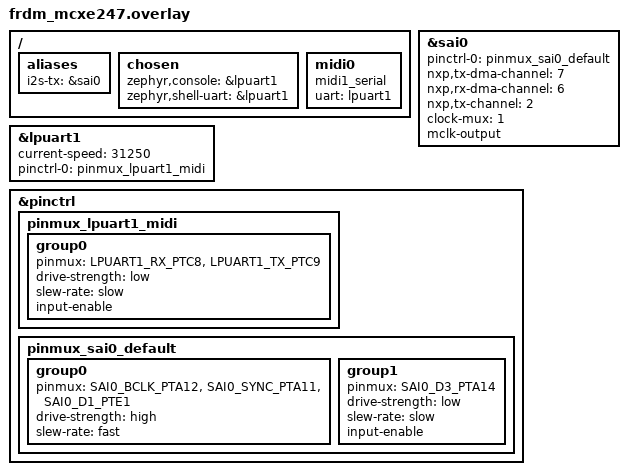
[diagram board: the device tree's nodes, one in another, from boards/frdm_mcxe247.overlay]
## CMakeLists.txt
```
# Copyright 2026 Jan-Willem Smaal <usenet@gispen.org>
# SPDX-License-Identifier: Apache-2.0

cmake_minimum_required(VERSION 3.20.0)
set(KCONFIG_ROOT ${CMAKE_CURRENT_SOURCE_DIR}/Kconfig)
find_package(Zephyr REQUIRED HINTS $ENV{ZEPHYR_BASE})
project(midi-synth)

set(GEN_LUTS_SCRIPT ${CMAKE_CURRENT_SOURCE_DIR}/scripts/gen_luts.py)
set(LUTS_HEADER ${CMAKE_CURRENT_BINARY_DIR}/include/synth_luts_generated.h)

add_custom_command(
    OUTPUT ${LUTS_HEADER}
    COMMAND ${CMAKE_COMMAND} -E make_directory ${CMAKE_CURRENT_BINARY_DIR}/include
    COMMAND python3 ${GEN_LUTS_SCRIPT} ${CONFIG_AUDIO_SAMPLE_RATE} ${LUTS_HEADER}
    DEPENDS ${GEN_LUTS_SCRIPT}
)

target_sources(app PRIVATE 
    src/main.c 
    src/audio.c 
    src/synth_engine.c
    src/midi_handler.c
    src/adsr.c
    src/waveform_selector.c
)

target_include_directories(app PRIVATE src ${CMAKE_CURRENT_BINARY_DIR}/include)
set_source_files_properties(src/synth_engine.c PROPERTIES OBJECT_DEPENDS ${LUTS_HEADER})
```

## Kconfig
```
# Copyright 2026 Jan-Willem Smaal <usenet@gispen.org>
# SPDX-License-Identifier: Apache-2.0

menu "MIDI Synth Options"

config AUDIO_SAMPLE_RATE
	int "Sample Rate (Hz)"
	default 96000
	help
	  System audio sample rate. Possible values 8000, 16000, 32000 etc.

config VOICECARD_VOICES
	int "Number of voices"
	default 16
	help
	  Number of voices support.  Multiples of 2.  2, 4, 8, 16 etc...

config AUDIO_BIT_WIDTH
	int "Sample Bit Width"
	default 16
	help
	  Audio bit depth (currently only 16 bit works!)

endmenu

source "Kconfig.zephyr"
```

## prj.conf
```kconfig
# Copyright 2026 Jan-Willem Smaal <usenet@gispen.org>
# SPDX-License-Identifier: Apache-2.0

# General
CONFIG_MAIN_STACK_SIZE=2048
CONFIG_BOOT_BANNER=y

# I2S and Audio
CONFIG_I2S=y
CONFIG_AUDIO_SAMPLE_RATE=96000
CONFIG_AUDIO_BIT_WIDTH=16

# CMSIS-DSP
CONFIG_DSP=y
CONFIG_CMSIS_DSP=y
CONFIG_CMSIS_DSP_FASTMATH=y

# MIDI 1.0 Library
CONFIG_MIDI1_SERIAL=y
CONFIG_MIDI1_SERIAL_ISR_MSGQ_SIZE_MS=128
CONFIG_MIDI1_HARMONIC=y
CONFIG_SERIAL=y
CONFIG_UART_INTERRUPT_DRIVEN=y

# GPIO
CONFIG_GPIO=y

# Logging
CONFIG_LOG=y
#CONFIG_LOG_DEFAULT_LEVEL=3
CONFIG_I2S_LOG_LEVEL_ERR=y

# Floating Point Support for Shell/Logging
CONFIG_CBPRINTF_FP_SUPPORT=y

# Synthesizer Configuration
CONFIG_VOICECARD_VOICES=32
```

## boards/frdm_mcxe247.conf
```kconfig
# Copyright 2026 Jan-Willem Smaal <usenet@gispen.org>
# SPDX-License-Identifier: Apache-2.0
CONFIG_I2S_HAS_PLL_SETTING=n
```

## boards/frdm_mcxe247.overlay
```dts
/*
 * Copyright 2026 Jan-Willem Smaal <usenet@gispen.org>
 * SPDX-License-Identifier: Apache-2.0
 */

#include <nxp/mcx/MCXE247VLQ-pinctrl.h>

/ {
	aliases {
		i2s-tx = &sai0;
	};

	chosen {
		/* MIDI/Console on mikroBUS UART (PTC8/PTC9) */
		zephyr,console = &lpuart1;
		zephyr,shell-uart = &lpuart1;
	};

	midi0: midi0 {
		status = "okay";
		compatible = "midi1_serial";
		uart = <&lpuart1>;
	};
};

&sai0 {
	status = "okay";
	pinctrl-0 = <&pinmux_sai0_default>;
	pinctrl-names = "default";
	
	/* REQUIRED properties from binding documentation */
	nxp,tx-dma-channel = <7>;
	nxp,rx-dma-channel = <6>;
	
	/* User Truth: J1 Pin 5 is PTE1 which is SAI0_D1 (Channel 1) */
	nxp,tx-channel = <2>; 
	
	/* Select standard functional clock for SAI root */
	clock-mux = <1>; 
	
	mclk-output;
};

/* MIDI/Console on mikroBUS UART (PTC8/PTC9) */
&lpuart1 {
	status = "okay";
	current-speed = <31250>;
	pinctrl-0 = <&pinmux_lpuart1_midi>;
	pinctrl-names = "default";
};

&pinctrl {
	/* Standard pins with input-enable for RX */
	pinmux_lpuart1_midi: pinmux_lpuart1_midi {
		group0 {
			pinmux = <LPUART1_RX_PTC8>,
				 <LPUART1_TX_PTC9>;
			drive-strength = "low";
			slew-rate = "slow";
			input-enable;
		};
	};

	/* SAI0 (Verified User Truth Mapping) */
	pinmux_sai0_default: pinmux_sai0_default {
		group0 {
			pinmux = <SAI0_BCLK_PTA12>,   /* J1 Pin 9  - Bit Clock */
				 <SAI0_SYNC_PTA11>,   /* J1 Pin 7  - Frame Sync (LRCK) */
				 <SAI0_D1_PTE1>;      /* J1 Pin 5  - Data Out (TX_DAT) */
			drive-strength = "high";
			slew-rate = "fast";
		};
		group1 {
			pinmux = <SAI0_D3_PTA14>;     /* J1 Pin 15 - Data In (RX_DAT) */
			drive-strength = "low";
			slew-rate = "slow";
			input-enable;
		};
	};
};
```

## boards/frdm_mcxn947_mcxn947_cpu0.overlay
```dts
/*
 * Copyright 2026 Jan-Willem Smaal <usenet@gispen.org>
 * SPDX-License-Identifier: Apache-2.0
 */

/ {
	aliases {
		i2s-tx = &sai1;
		sw2    = &user_button_2;
	};

	midi0: midi0 {
		status = "okay";
		compatible = "midi1_serial";
		uart = <&flexcomm2_lpuart2>;
	};
};

/* Enable SW2 (defined but disabled in the upstream board DTSI) */
&user_button_2 {
	status = "okay";
};

&sai1 {
	status = "okay";
	pinctrl-0 = <&pinmux_sai1_custom>;
	pinctrl-names = "default";
	nxp,tx-channel = <1>; /* Bitmask: 1 = Channel 0 (TXD0) */
	mclk-output;          /* MANDATORY for MCXN947 */
};

/* MIDI on Arduino D0/D1 */
&flexcomm2_lpuart2 {
	status = "okay";
	current-speed = <31250>;
};

&pinctrl {
	pinmux_sai1_custom: pinmux_sai1_custom {
		group0 {
			pinmux = <SAI1_TX_BCLK_PIO3_16>,   /* J1 Pin 1  - Bit Clock */
				 <SAI1_TX_FS_PIO3_17>,     /* J1 Pin 11 - Frame Sync (LRCK) */
				 <SAI1_TXD0_PIO3_20>,      /* J1 Pin 5  - Data Out */
				 <SAI1_RX_BCLK_PIO3_18>;   /* J1 Pin 9  - Bit Clock (Shared) */
			drive-strength = "high";
			slew-rate = "fast";
			input-enable;
		};
	};
};
```

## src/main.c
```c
/*
 * Copyright 2026 Jan-Willem Smaal <usenet@gispen.org>
 * SPDX-License-Identifier: Apache-2.0
 */

/**
 * @file main.c
 * @brief MIDI Sine Wave Synthesizer Main Entry Point
 * @author Jan-Willem Smaal <usenet@gispen.org>
 */

#include <zephyr/kernel.h>
#include <zephyr/logging/log.h>
#include <zephyr/drivers/i2s.h>
#include "audio.h"
#include "synth_engine.h"
#include "midi_handler.h"
#include "waveform_selector.h"

LOG_MODULE_REGISTER(midi_synth, CONFIG_LOG_DEFAULT_LEVEL);

K_MEM_SLAB_DEFINE_STATIC(rx_slab, 512, 16, 32); /**< Dummy for clock generator */

static const struct device *const i2s_dev = DEVICE_DT_GET(DT_ALIAS(i2s_tx));

static int configure_rx(void)
{
	struct i2s_config conf;

	conf.word_size = CONFIG_AUDIO_BIT_WIDTH;
	conf.channels = 2;
	conf.format = I2S_FMT_DATA_FORMAT_I2S;
	conf.options = I2S_OPT_BIT_CLK_CONTROLLER | I2S_OPT_FRAME_CLK_CONTROLLER;
	conf.frame_clk_freq = CONFIG_AUDIO_SAMPLE_RATE;
	conf.block_size = 128 * 2 * (CONFIG_AUDIO_BIT_WIDTH / 8);
	conf.timeout = 50;
	conf.mem_slab = &rx_slab;

	return i2s_configure(i2s_dev, I2S_DIR_RX, &conf);
}

/**
 * @brief RX Sink Thread
 * Drains the dummy RX queue to keep clock generation running without ENOMEM.
 */
static void rx_sink_thread_fn(void *p1, void *p2, void *p3)
{
	void *rx_buffer;
	size_t size;
	int ret;

	ARG_UNUSED(p1);
	ARG_UNUSED(p2);
	ARG_UNUSED(p3);

	while (1) {
		ret = i2s_read(i2s_dev, &rx_buffer, &size);
		if (ret == 0) {
			k_mem_slab_free(&rx_slab, rx_buffer);
		} else {
			/* For any error (including -EAGAIN from a timeout or -EIO from overrun), drop and restart the stream */
			LOG_WRN("I2S RX error %d — resetting RX stream", ret);
			i2s_trigger(i2s_dev, I2S_DIR_RX, I2S_TRIGGER_DROP);
			ret = configure_rx();
			if (ret < 0) {
				LOG_ERR("I2S RX reconfigure failed: %d", ret);
			}

			/* Attempt to restart RX stream */
			ret = i2s_trigger(i2s_dev, I2S_DIR_RX, I2S_TRIGGER_START);
			if (ret < 0) {
				LOG_ERR("Failed to restart I2S RX: %d", ret);
				k_sleep(K_MSEC(10));
			}
		}
	}
}

K_THREAD_DEFINE(rx_sink_tid, 1024, rx_sink_thread_fn, NULL, NULL, NULL, -3, 0, K_TICKS_FOREVER);

int main(void)
{
	int ret;

	/* Application Banner */
	LOG_INF("\n\n");
	LOG_INF("##############################################");
	LOG_INF("# MIDI Polyphonic Sine Synthesizer");
	LOG_INF("# By: Jan-Willem Smaal <usenet@gispen.org>");
	LOG_INF("# Hardware: %-26s", CONFIG_BOARD_TARGET);
	LOG_INF("# Build:    %-26s", __DATE__ " " __TIME__);
	LOG_INF("##############################################");
	LOG_INF("Initializing system components...");

	if (!device_is_ready(i2s_dev)) {
		LOG_ERR("I2S device not ready for RX clock generation");
		return -ENODEV;
	}

	ret = configure_rx();
	if (ret < 0) {
		LOG_ERR("I2S RX configure failed: %d", ret);
		return ret;
	}

	/* Initialize Synthesizer DSP */
	synth_engine_init();

	/* Initialize Audio System */
	ret = audio_system_init();
	if (ret < 0) {
		LOG_ERR("Audio system initialization failed: %d", ret);
		return ret;
	}

	/* Initialize MIDI System */
	ret = midi_system_init();
	if (ret < 0) {
		LOG_ERR("MIDI system initialization failed: %d", ret);
		return ret;
	}

	/* Initialize waveform selector (SW2) */
	ret = waveform_selector_init();
	if (ret < 0) {
		LOG_ERR("Waveform selector initialization failed: %d", ret);
		return ret;
	}

	/* Start Clocks (via RX) */
	ret = i2s_trigger(i2s_dev, I2S_DIR_RX, I2S_TRIGGER_START);
	if (ret < 0) {
		LOG_WRN("I2S RX (Clocks) start failed: %d", ret);
	}
	k_thread_start(rx_sink_tid);

	LOG_INF("System operational.");

	while (1) {
		k_sleep(K_FOREVER);
	}

	return 0;
}
```

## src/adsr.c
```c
/*
 * Copyright 2026 Jan-Willem Smaal <usenet@gispen.org>
 * SPDX-License-Identifier: Apache-2.0
 */

/**
 * @file adsr.c
 * @brief ADSR implementation
 * @author Jan-Willem Smaal <usenet@gispen.org>
 */
#include "adsr.h"

void adsr_trigger_on(struct adsr *padsr, struct adsr_param param)
{
	padsr->state = ATTACK;
	padsr->lifetime = param.attack;
	padsr->initial_lifetime = param.attack;
	padsr->start_gain = 0;
	padsr->gain_accum = 0;

	if (param.attack > 0) {
		padsr->gain_step = ((int32_t)32767 << 16) / (int32_t)param.attack;
	} else {
		padsr->gain_step = 0;
		padsr->gain_accum = (int32_t)32767 << 16;
	}
	padsr->current_gain = (q15_t)(padsr->gain_accum >> 16);
}

void adsr_trigger_off(struct adsr *padsr, struct adsr_param param)
{
	padsr->state = RELEASE;
	padsr->lifetime = param.release;
	padsr->initial_lifetime = param.release;
	padsr->start_gain = padsr->current_gain;
	padsr->gain_accum = (int32_t)padsr->start_gain << 16;

	if (param.release > 0) {
		padsr->gain_step = -((int32_t)padsr->start_gain << 16) / (int32_t)param.release;
	} else {
		padsr->gain_step = 0;
		padsr->gain_accum = 0;
	}
	padsr->current_gain = (q15_t)(padsr->gain_accum >> 16);
}

enum adsr_state adsr_process(struct adsr *padsr, struct adsr_param param, uint32_t delta_samples,
			     bool use_log)
{
	enum adsr_state ret_state = padsr->state;
	uint32_t active_delta = delta_samples;

	/* Don't do anything when we are in the END state */
	if (ret_state == END) {
		padsr->lifetime = 0;
		return ret_state;
	}

	bool keep_transitioning = true;

	/* State transition when lifetime expires */
	while (padsr->lifetime == 0 && padsr->state != END && keep_transitioning) {
		padsr->start_gain = padsr->current_gain;
		switch (padsr->state) {
		case ATTACK:
			padsr->state = DECAY;
			padsr->lifetime = param.decay;
			padsr->initial_lifetime = param.decay;
			padsr->gain_accum = (int32_t)padsr->start_gain << 16;
			if (param.decay > 0) {
				int32_t target_gain = padsr->sustain_level;

				padsr->gain_step = ((target_gain - padsr->start_gain) << 16) / (int32_t)param.decay;
			} else {
				padsr->gain_step = 0;
				padsr->gain_accum = (int32_t)padsr->sustain_level << 16;
			}
			padsr->current_gain = (q15_t)(padsr->gain_accum >> 16);
			break;
		case DECAY:
			padsr->state = SUSTAIN;
			padsr->lifetime = param.sustain;
			padsr->initial_lifetime = param.sustain;
			padsr->gain_accum = (int32_t)padsr->sustain_level << 16;
			padsr->gain_step = 0;
			padsr->current_gain = padsr->sustain_level;
			break;
		case SUSTAIN:
			if (param.sustain > 0) {
				padsr->state = RELEASE;
				padsr->lifetime = param.release;
				padsr->initial_lifetime = param.release;
				padsr->gain_accum = (int32_t)padsr->current_gain << 16;
				if (param.release > 0) {
					padsr->gain_step = -((int32_t)padsr->current_gain << 16) / (int32_t)param.release;
				} else {
					padsr->gain_step = 0;
					padsr->gain_accum = 0;
				}
				padsr->current_gain = (q15_t)(padsr->gain_accum >> 16);
			} else {
				keep_transitioning = false;
			}
			break;
		case RELEASE:
			padsr->state = END;
			padsr->lifetime = 0;
			padsr->initial_lifetime = 0;
			padsr->gain_accum = 0;
			padsr->gain_step = 0;
			padsr->current_gain = 0;
			break;
		default:
			keep_transitioning = false;
			break;
		}
	}

	if (padsr->state == END) {
		padsr->lifetime = 0;
		return ret_state;
	}

	/* Subtract the delta from the lifetime */
	if (active_delta >= padsr->lifetime) {
		active_delta = padsr->lifetime;
		padsr->lifetime = 0;
	} else {
		padsr->lifetime = padsr->lifetime - active_delta;
	}

	/* Perform incremental step accumulation */
	switch (padsr->state) {
	case ATTACK:
	case DECAY:
	case RELEASE:
		padsr->gain_accum += padsr->gain_step * active_delta;
		/* Boundary clamping */
		if (padsr->state == ATTACK) {
			if (padsr->gain_accum > ((int32_t)32767 << 16)) {
				padsr->gain_accum = (int32_t)32767 << 16;
			}
		} else if (padsr->state == DECAY) {
			if (padsr->gain_step < 0) {
				if (padsr->gain_accum < ((int32_t)padsr->sustain_level << 16)) {
					padsr->gain_accum = (int32_t)padsr->sustain_level << 16;
				}
			} else if (padsr->gain_step > 0) {
				if (padsr->gain_accum > ((int32_t)padsr->sustain_level << 16)) {
					padsr->gain_accum = (int32_t)padsr->sustain_level << 16;
				}
			}
		} else if (padsr->state == RELEASE) {
			if (padsr->gain_accum < 0) {
				padsr->gain_accum = 0;
			}
		}
		padsr->current_gain = (q15_t)(padsr->gain_accum >> 16);
		break;
	case SUSTAIN:
		padsr->current_gain = padsr->sustain_level;
		break;
	case END:
		padsr->current_gain = 0;
		break;
	}

	if (use_log) {
		padsr->current_gain =
			(q15_t)(((int32_t)padsr->current_gain * padsr->current_gain) >> 15);
	}

	return ret_state;
}

/* EOF */
```

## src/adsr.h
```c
/*
 * Copyright 2026 Jan-Willem Smaal <usenet@gispen.org>
 * SPDX-License-Identifier: Apache-2.0
 */

/**
 * @file adsr.h
 * @brief ADSR implementation
 * @author Jan-Willem Smaal <usenet@gispen.org>
 */
#ifndef ADSR_H
#define ADSR_H
#include <stdint.h>
#include <stdbool.h>
#include <zephyr/dsp/types.h>

/*
 * ADSR background:
 * So for every voice that is sounding each should have it's
 * own "counter" on how long we are in the certain state.
 * When the lifetime of the state expires we need to move to the next
 * state. The state of the 'adsr' dicates the amount of attenuation of
 * the periodic wave. The length is a fixed value so it's independent of note frequency.
 * For volume based ADSR we need logarithmic calculations for things
 * like pitch and filter cutoff etc.. we need linear.
 */

struct adsr_param {
	uint32_t attack;
	uint32_t decay;
	uint32_t sustain;
	uint32_t release;
	uint32_t end;
};

enum adsr_state {
	ATTACK,
	DECAY,
	SUSTAIN,
	RELEASE,
	END,
};

struct adsr {
	enum adsr_state state;
	q15_t sustain_level;
	uint32_t lifetime; /* counter for the remaining lifetime */
	uint32_t initial_lifetime;
	q15_t current_gain; /* This is calculated inside adsr_process */
	q15_t start_gain;   /* Gain at the start of the current phase */
	int32_t gain_accum; /**< Q16.16 accumulator for current gain */
	int32_t gain_step;  /**< Q16.16 gain change per sample */
};

/**
 * @brief Trigger the note-on event for the ADSR envelope
 * @param padsr Pointer to the ADSR state structure
 * @param param ADSR parameter configuration
 */
void adsr_trigger_on(struct adsr *padsr, struct adsr_param param);

/**
 * @brief Trigger the note-off event for the ADSR envelope
 * @param padsr Pointer to the ADSR state structure
 * @param param ADSR parameter configuration
 */
void adsr_trigger_off(struct adsr *padsr, struct adsr_param param);

enum adsr_state adsr_process(struct adsr *padsr, struct adsr_param adsr_param,
			     uint32_t delta_samples, bool use_log);

#endif
/* EOF */
```

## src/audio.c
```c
/*
 * Copyright 2026 Jan-Willem Smaal <usenet@gispen.org>
 * SPDX-License-Identifier: Apache-2.0
 */

/**
 * @file audio.c
 * @brief Real-time audio generation thread
 * @author Jan-Willem Smaal <usenet@gispen.org>
 */

#include <zephyr/kernel.h>
#include <zephyr/drivers/i2s.h>
#include <zephyr/logging/log.h>
#include "audio.h"
#include "synth_engine.h"

LOG_MODULE_DECLARE(midi_synth, CONFIG_LOG_DEFAULT_LEVEL);

/* --- Audio Constants --- */
#define SAMPLES_PER_BLOCK 128
#define CHANNELS          2
#define FRAME_SIZE        (SAMPLES_PER_BLOCK * CHANNELS * sizeof(int16_t))

/* Memory slab for I2S TX blocks */
K_MEM_SLAB_DEFINE_STATIC(audio_slab, FRAME_SIZE, 16, 32);

static const struct device *const i2s_dev = DEVICE_DT_GET(DT_ALIAS(i2s_tx));

static int configure_tx(void)
{
	struct i2s_config conf;

	conf.word_size = CONFIG_AUDIO_BIT_WIDTH;
	conf.channels = 2;
	conf.format = I2S_FMT_DATA_FORMAT_I2S;
	conf.options = I2S_OPT_BIT_CLK_CONTROLLER | I2S_OPT_FRAME_CLK_CONTROLLER;
	conf.frame_clk_freq = CONFIG_AUDIO_SAMPLE_RATE;
	conf.block_size = SAMPLES_PER_BLOCK * CHANNELS * sizeof(int16_t);
	conf.timeout = 50;
	conf.mem_slab = &audio_slab;

	return i2s_configure(i2s_dev, I2S_DIR_TX, &conf);
}

/**
 * @brief Audio Generation Thread
 */
static void audio_thread_fn(void *p1, void *p2, void *p3)
{
	int ret;
	void *tx_buffer;
	bool started = false;

	LOG_INF("Audio Thread Started");

	while (1) {
		ret = k_mem_slab_alloc(&audio_slab, &tx_buffer, K_FOREVER);
		if (ret < 0) {
			continue;
		}

		/* Fill buffer from DSP engine */
		synth_engine_render_block((int16_t *)tx_buffer, SAMPLES_PER_BLOCK);

		ret = i2s_write(i2s_dev, tx_buffer, FRAME_SIZE);
		if (ret < 0) {
			k_mem_slab_free(&audio_slab, tx_buffer);
			/*
			 * Any error (including -EAGAIN from a timeout or -EIO from
			 * an underrun) means the I2S TX pipeline has stopped.
			 * Issue DROP to flush it back to a known idle state,
			 * reset the started flag so the next successful write
			 * re-triggers the peripheral, and continue.
			 * The thread must never exit permanently.
			 */
			LOG_WRN("I2S write error %d — dropping TX pipeline, restarting",
				ret);
			i2s_trigger(i2s_dev, I2S_DIR_TX, I2S_TRIGGER_DROP);
			ret = configure_tx();
			if (ret < 0) {
				LOG_ERR("I2S TX reconfigure failed: %d", ret);
			}
			started = false;
			continue;
		}

		if (!started) {
			ret = i2s_trigger(i2s_dev, I2S_DIR_TX, I2S_TRIGGER_START);
			if (ret < 0) {
				LOG_ERR("I2S TX start failed: %d", ret);
				return;
			}
			started = true;
		}
	}
}

K_THREAD_DEFINE(audio_tid, 2048, audio_thread_fn, NULL, NULL, NULL, 1, 0, K_TICKS_FOREVER);

int audio_system_init(void)
{
	int ret;

	if (!device_is_ready(i2s_dev)) {
		LOG_ERR("I2S device not ready");
		return -ENODEV;
	}

	ret = configure_tx();
	if (ret < 0) {
		LOG_ERR("I2S TX configure failed: %d", ret);
		return ret;
	}

	k_thread_start(audio_tid);

	return 0;
}
```

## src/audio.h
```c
/*
 * Copyright 2026 Jan-Willem Smaal <usenet@gispen.org>
 * SPDX-License-Identifier: Apache-2.0
 */

/**
 * @file audio.h
 * @brief Audio system API
 * @author Jan-Willem Smaal <usenet@gispen.org>
 */

#ifndef AUDIO_H
#define AUDIO_H

/**
 * @brief Initialize the audio system
 *
 * @return 0 on success, negative error code on failure
 */
int audio_system_init(void);

#endif /* AUDIO_H */
```

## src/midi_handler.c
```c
/*
 * Copyright 2026 Jan-Willem Smaal <usenet@gispen.org>
 * SPDX-License-Identifier: Apache-2.0
 */

/**
 * @file midi_handler.c
 * @brief MIDI 1.0 UART processing thread and callbacks
 * @author Jan-Willem Smaal <usenet@gispen.org>
 */

#include <zephyr/kernel.h>
#include <zephyr/logging/log.h>
#include <zephyr/drivers/midi/midi1_serial.h>
#include <zephyr/midi1/note.h>
#include "synth_engine.h"
#include "midi_handler.h"

LOG_MODULE_DECLARE(midi_synth, CONFIG_LOG_DEFAULT_LEVEL);

/**
 * @brief Callback for MIDI Note On events
 */
static void midi_note_on_cb(uint8_t channel, uint8_t note, uint8_t velocity)
{
	struct synth_event evt = {
		.type = SYNTH_EVT_NOTE_ON,
		.note = note,
		.velocity = velocity,
		.patch_idx = (uint8_t)synth_get_active_patch_idx(),
	};

	synth_submit_event(&evt);

	LOG_DBG("Note On  | Ch: %2d | Note: %3d (%-4s) | Vel: %3d", channel + 1, note,
		harm_note_to_text_with_octave(note, false), velocity);
}

/**
 * @brief Callback for MIDI Note Off events
 */
static void midi_note_off_cb(uint8_t channel, uint8_t note, uint8_t velocity)
{
	struct synth_event evt = {
		.type = SYNTH_EVT_NOTE_OFF,
		.note = note,
		.velocity = velocity,
	};

	synth_submit_event(&evt);

	LOG_DBG("Note Off | Ch: %2d | Note: %3d (%-4s)", channel + 1, note,
		harm_note_to_text_with_octave(note, false));
}

static struct midi1_serial_callbacks midi_cb = {
	.note_on = midi_note_on_cb,
	.note_off = midi_note_off_cb,
};

/**
 * @brief MIDI Processing Thread
 */
static void midi_thread_fn(void *p1, void *p2, void *p3)
{
	const struct device *midi_dev = DEVICE_DT_GET(DT_NODELABEL(midi0));

	LOG_INF("MIDI Thread Started");

	while (1) {
		/* Blocking call that parses incoming UART bytes */
		midi1_serial_receiveparser(midi_dev);
	}
}

K_THREAD_DEFINE(midi_tid, 1024, midi_thread_fn, NULL, NULL, NULL, 0, 0, K_TICKS_FOREVER);

int midi_system_init(void)
{
	LOG_INF("MIDI system init");
	const struct device *midi_dev = DEVICE_DT_GET(DT_NODELABEL(midi0));

	if (!device_is_ready(midi_dev)) {
		LOG_ERR("MIDI device not ready");
		return -ENODEV;
	}

	midi1_serial_register_callbacks(midi_dev, &midi_cb);

	k_thread_start(midi_tid);

	return 0;
}
```

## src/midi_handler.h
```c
/*
 * Copyright 2026 Jan-Willem Smaal <usenet@gispen.org>
 * SPDX-License-Identifier: Apache-2.0
 */

/**
 * @file midi_handler.h
 * @brief MIDI input system API
 * @author Jan-Willem Smaal <usenet@gispen.org>
 */

#ifndef MIDI_HANDLER_H
#define MIDI_HANDLER_H

/**
 * @brief Initialize the MIDI input system
 *
 * @return 0 on success, negative error code on failure
 */
int midi_system_init(void);

#endif /* MIDI_HANDLER_H */
```

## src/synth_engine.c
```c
/*
 * Copyright 2026 Jan-Willem Smaal <usenet@gispen.org>
 * SPDX-License-Identifier: Apache-2.0
 */

/**
 * @file synth_engine.c
 * @brief Digital Signal Processing core for the synthesizer
 * @author Jan-Willem Smaal <usenet@gispen.org>
 * @date 2026-06-16
 */

#include <zephyr/kernel.h>
#include <zephyr/logging/log.h>
#include <zephyr/sys/util.h>
#include "synth_engine.h"
#include "adsr.h"

/* This LUT is generated during the build process */
#include "synth_luts_generated.h"

LOG_MODULE_DECLARE(midi_synth, CONFIG_LOG_DEFAULT_LEVEL);

/* Look at the Kconfig */
#define MAX_VOICES CONFIG_VOICECARD_VOICES

#if MAX_VOICES <= 1
#define MIXER_SHIFT 0
#elif MAX_VOICES <= 2
#define MIXER_SHIFT 1
#elif MAX_VOICES <= 4
#define MIXER_SHIFT 2
#elif MAX_VOICES <= 8
#define MIXER_SHIFT 3
#elif MAX_VOICES <= 16
#define MIXER_SHIFT 4
#elif MAX_VOICES <= 32
#define MIXER_SHIFT 5
#else
#define MIXER_SHIFT 5
#endif

/** @brief Control rate period in samples (determines ADSR update frequency) */
#define CONTROL_RATE_PERIOD 16U

/* Event Queue for Synthesizer Core */
K_MSGQ_DEFINE(synth_evt_queue, sizeof(struct synth_event), 32, 4);

/**
 * @brief Represents a single "Voice Card"
 */
struct voice_card {
	bool gate_open;       /**< Envelope gate status */
	struct adsr envelope; /**< Voice's ADSR state */
	enum synth_wave wave; /**< Active waveform for this voice */
	uint8_t note;         /**< MIDI note number */
	q15_t velocity_scale; /**< Amplitude scale factor (Q15) */
	uint32_t phase_inc;   /**< 32-bit phase increment */
	uint32_t phase_acc;   /**< 32-bit phase accumulator */
	uint32_t age;         /**< Age tracker for voice stealing */
	q15_t pan_l;          /**< Stereo left panning weight (Q15) */
	q15_t pan_r;          /**< Stereo right panning weight (Q15) */
};

/**
 * @brief Internal synthesizer state
 */
struct synth_state {
	struct voice_card voices[MAX_VOICES];
	uint32_t note_counter;
	atomic_t active_patch_idx; /**< Global active patch index (atomic) */
};

#define MS_TO_SAMPLES(ms) (((uint64_t)(ms) * CONFIG_AUDIO_SAMPLE_RATE) / 1000)

/**
 * @brief Presets table
 */
static const struct patch g_patches[] = {
	{
		.name = "SAW",
		.layer_count = 1,
		.wave = { SYNTH_WAVE_SAW },
		.octave_shift = { 0 },
		.unison_count = 1,
		.detune_cents = 0,
		.env = {
			.attack = MS_TO_SAMPLES(20),
			.decay = MS_TO_SAMPLES(50),
			.sustain = 0xffffffff,
			.release = MS_TO_SAMPLES(800),
			.end = 0,
		}
	},
	{
		.name = "SINE",
		.layer_count = 1,
		.wave = { SYNTH_WAVE_SINE },
		.octave_shift = { 0 },
		.unison_count = 1,
		.detune_cents = 0,
		.env = {
			.attack = MS_TO_SAMPLES(20),
			.decay = MS_TO_SAMPLES(50),
			.sustain = 0xffffffff,
			.release = MS_TO_SAMPLES(800),
			.end = 0,
		}
	},
	{
		.name = "SQUARE",
		.layer_count = 1,
		.wave = { SYNTH_WAVE_SQUARE },
		.octave_shift = { 0 },
		.unison_count = 1,
		.detune_cents = 0,
		.env = {
			.attack = MS_TO_SAMPLES(20),
			.decay = MS_TO_SAMPLES(50),
			.sustain = 0xffffffff,
			.release = MS_TO_SAMPLES(800),
			.end = 0,
		}
	},
	{
		.name = "TRIANGLE",
		.layer_count = 1,
		.wave = { SYNTH_WAVE_TRI },
		.octave_shift = { 0 },
		.unison_count = 1,
		.detune_cents = 0,
		.env = {
			.attack = MS_TO_SAMPLES(20),
			.decay = MS_TO_SAMPLES(50),
			.sustain = 0xffffffff,
			.release = MS_TO_SAMPLES(800),
			.end = 0,
		}
	},
	{
		.name = "SUPER SAW",
		.layer_count = 1,
		.wave = { SYNTH_WAVE_SAW },
		.octave_shift = { 0 },
		.unison_count = 3,
		.detune_cents = 30,
		.env = {
			.attack = MS_TO_SAMPLES(10),
			.decay = MS_TO_SAMPLES(80),
			.sustain = 0xffffffff,
			.release = MS_TO_SAMPLES(600),
			.end = 0,
		}
	},
	{
		.name = "STRINGS",
		.layer_count = 1,
		.wave = { SYNTH_WAVE_SAW },
		.octave_shift = { 0 },
		.unison_count = 2,
		.detune_cents = 10,
		.env = {
			.attack = MS_TO_SAMPLES(800),
			.decay = MS_TO_SAMPLES(200),
			.sustain = 0xffffffff,
			.release = MS_TO_SAMPLES(1200),
			.end = 0,
		}
	},
	{
		.name = "SAW+SUB",
		.layer_count = 2,
		.wave = { SYNTH_WAVE_SAW, SYNTH_WAVE_SINE },
		.octave_shift = { 0, -1 },
		.unison_count = 1,
		.detune_cents = 0,
		.env = {
			.attack = MS_TO_SAMPLES(20),
			.decay = MS_TO_SAMPLES(50),
			.sustain = 0xffffffff,
			.release = MS_TO_SAMPLES(800),
			.end = 0,
		}
	}
};

static const int16_t *const wave_table[SYNTH_WAVE_COUNT] = {
	[SYNTH_WAVE_SINE]   = wave_lut_sine,
	[SYNTH_WAVE_SAW]    = wave_lut_saw,
	[SYNTH_WAVE_SQUARE] = wave_lut_square,
	[SYNTH_WAVE_TRI]    = wave_lut_tri,
};

static struct synth_state m_synth_state = {
	.note_counter = 0,
	.active_patch_idx = ATOMIC_INIT(0),
};

#define SUSTAIN_LEVEL 32000U

void synth_engine_init(void)
{
	for (int i = 0; i < MAX_VOICES; i++) {
		m_synth_state.voices[i].gate_open = false;
		m_synth_state.voices[i].wave = SYNTH_WAVE_SAW;
		m_synth_state.voices[i].phase_acc = 0;
		m_synth_state.voices[i].age = 0;
		m_synth_state.voices[i].envelope.state = END;
		m_synth_state.voices[i].envelope.sustain_level = SUSTAIN_LEVEL;
		m_synth_state.voices[i].envelope.lifetime = 0;
		m_synth_state.voices[i].envelope.initial_lifetime = 0;
		m_synth_state.voices[i].envelope.current_gain = 0;
		m_synth_state.voices[i].pan_l = 32767;
		m_synth_state.voices[i].pan_r = 32767;
	}
	atomic_set(&m_synth_state.active_patch_idx, 0);
	LOG_INF("Synth Engine Initialized");
}

void synth_submit_event(struct synth_event *evt)
{
	/* Ignore failures if queue is full to prevent blocking MIDI UART */
	k_msgq_put(&synth_evt_queue, evt, K_NO_WAIT);
}

static int count_active_voices(void)
{
	int active = 0;

	for (int i = 0; i < MAX_VOICES; i++) {
		if (m_synth_state.voices[i].envelope.state != END) {
			active++;
		}
	}
	return active;
}

static void handle_note_on(uint8_t note, uint8_t velocity, uint8_t patch_idx)
{
	if (patch_idx >= ARRAY_SIZE(g_patches)) {
		return;
	}

	const struct patch *p = &g_patches[patch_idx];
	uint8_t total_voices_needed = p->layer_count * p->unison_count;

	if (total_voices_needed == 0) {
		return;
	}

	for (uint8_t l = 0; l < p->layer_count; l++) {
		int shifted_note = (int)note + (int)p->octave_shift[l] * 12;

		if (shifted_note < 0) {
			shifted_note = 0;
		} else if (shifted_note > 127) {
			shifted_note = 127;
		}

		uint32_t base_phase_inc = phase_inc_lut[shifted_note];

		for (uint8_t u = 0; u < p->unison_count; u++) {
			int voice_to_use = -1;
			int stolen_voice = -1;
			bool needs_reset = false;

			/* Pass 1: find a fully silent (END) slot */
			for (int i = 0; i < MAX_VOICES; i++) {
				if (m_synth_state.voices[i].envelope.state == END) {
					voice_to_use = i;
					adsr_trigger_on(&m_synth_state.voices[i].envelope, p->env);
					break;
				}
			}

			/* Pass 2: find the quietest voice in RELEASE */
			if (voice_to_use == -1) {
				int32_t min_gain = 32768;

				for (int i = 0; i < MAX_VOICES; i++) {
					if (m_synth_state.voices[i].envelope.state == RELEASE &&
					    (int32_t)m_synth_state.voices[i].envelope.current_gain < min_gain) {
						min_gain = m_synth_state.voices[i].envelope.current_gain;
						stolen_voice = i;
					}
				}
				if (stolen_voice != -1) {
					voice_to_use = stolen_voice;
					needs_reset = true;
				}
			}

			/* Pass 3: last resort — steal the oldest held note */
			if (voice_to_use == -1) {
				uint32_t oldest_age = 0xFFFFFFFF;

				for (int i = 0; i < MAX_VOICES; i++) {
					if (m_synth_state.voices[i].age <= oldest_age) {
						oldest_age = m_synth_state.voices[i].age;
						stolen_voice = i;
					}
				}
				if (stolen_voice != -1) {
					voice_to_use = stolen_voice;
					needs_reset = true;
				}
			}

			/* Reset envelope state if voice was stolen */
			if (needs_reset && voice_to_use != -1) {
				adsr_trigger_on(&m_synth_state.voices[voice_to_use].envelope, p->env);
			}

			if (voice_to_use != -1) {
				int32_t cents = 0;

				if (p->unison_count > 1) {
					cents = -p->detune_cents / 2 + (p->detune_cents * u) / (p->unison_count - 1);
				}

				uint32_t phase_inc_detuned = (uint32_t)(((uint64_t)base_phase_inc * (1731 + cents)) / 1731);

				q15_t pan_l, pan_r;

				if (p->unison_count > 1) {
					pan_r = (q15_t)((u * 32767) / (p->unison_count - 1));
					pan_l = 32767 - pan_r;
				} else {
					pan_l = 32767;
					pan_r = 32767;
				}

				m_synth_state.voices[voice_to_use].note = note;
				m_synth_state.voices[voice_to_use].wave = p->wave[l];
				m_synth_state.voices[voice_to_use].phase_inc = phase_inc_detuned;
				m_synth_state.voices[voice_to_use].phase_acc = 0;
				m_synth_state.voices[voice_to_use].velocity_scale = velocity_lut[velocity & 0x7F];
				m_synth_state.voices[voice_to_use].gate_open = true;
				m_synth_state.voices[voice_to_use].age = ++m_synth_state.note_counter;
				m_synth_state.voices[voice_to_use].pan_l = pan_l;
				m_synth_state.voices[voice_to_use].pan_r = pan_r;

				LOG_INF("Voice On:  Note %d -> Slot %d (Active: %d/%d)",
					note, voice_to_use, count_active_voices(), MAX_VOICES);
			}
		}
	}
}

static void handle_note_off(uint8_t note)
{
	int patch_idx = (int)atomic_get(&m_synth_state.active_patch_idx);
	const struct patch *active_patch = &g_patches[patch_idx];

	for (int i = 0; i < MAX_VOICES; i++) {
		struct voice_card *v_ptr = &m_synth_state.voices[i];

		if (v_ptr->note == note && v_ptr->envelope.state != END) {
			adsr_trigger_off(&v_ptr->envelope, active_patch->env);
			LOG_DBG("Voice Off: Note %d -> Slot %d (Active: %d/%d)",
				note, i, count_active_voices(), MAX_VOICES);
		}
		if (v_ptr->envelope.state == END) {
			v_ptr->gate_open = false;
		}
	}
}

static void handle_set_patch(uint8_t patch_idx)
{
	if (patch_idx >= ARRAY_SIZE(g_patches)) {
		return;
	}

	atomic_set(&m_synth_state.active_patch_idx, (atomic_val_t)patch_idx);

	const struct patch *p = &g_patches[patch_idx];

	/* Propagate new first-layer waveform immediately to active sounding voices */
	for (int i = 0; i < MAX_VOICES; i++) {
		if (m_synth_state.voices[i].envelope.state != END) {
			m_synth_state.voices[i].wave = p->wave[0];
		}
	}
	LOG_INF("Patch -> %s", p->name);
}

static void process_events(void)
{
	struct synth_event evt;

	while (k_msgq_get(&synth_evt_queue, &evt, K_NO_WAIT) == 0) {
		if (evt.type == SYNTH_EVT_NOTE_ON) {
			handle_note_on(evt.note, evt.velocity, evt.patch_idx);
		} else if (evt.type == SYNTH_EVT_NOTE_OFF) {
			handle_note_off(evt.note);
		} else if (evt.type == SYNTH_EVT_SET_PATCH) {
			handle_set_patch(evt.patch_idx);
		}
	}
}

int synth_get_active_patch_idx(void)
{
	return (int)atomic_get(&m_synth_state.active_patch_idx);
}

const struct patch *synth_get_patch(int idx)
{
	if (idx < 0 || idx >= ARRAY_SIZE(g_patches)) {
		return NULL;
	}
	return &g_patches[idx];
}

int synth_get_patch_count(void)
{
	return (int)ARRAY_SIZE(g_patches);
}

void synth_engine_render_block(int16_t *buffer, uint32_t samples)
{
	/* Process any pending events before rendering the block */
	process_events();

	/* Get the active patch to use its envelope parameters */
	int patch_idx = (int)atomic_get(&m_synth_state.active_patch_idx);
	const struct patch *active_patch = &g_patches[patch_idx];

	uint32_t rendered = 0;

	while (rendered < samples) {
		uint32_t chunk = MIN(CONTROL_RATE_PERIOD, samples - rendered);

		/* Process the ADSR values for all voices at the control rate */
		for (int v = 0; v < MAX_VOICES; v++) {
			adsr_process(&m_synth_state.voices[v].envelope, active_patch->env, chunk, true);
		}

		/* Render audio samples for the current control period */
		for (uint32_t i = 0; i < chunk; i++) {
			int32_t accumulator_l = 0;
			int32_t accumulator_r = 0;
			uint32_t buf_idx = rendered + i;

			for (int v = 0; v < MAX_VOICES; v++) {
				struct voice_card *v_ptr = &m_synth_state.voices[v];

				if (v_ptr->envelope.state != END) {
					uint16_t lut_idx = (uint16_t)(v_ptr->phase_acc >> WAVE_LUT_SHIFT);
					q15_t raw_sample = wave_table[v_ptr->wave][lut_idx];

					v_ptr->phase_acc += v_ptr->phase_inc;

					int32_t sample_vol = (v_ptr->velocity_scale * v_ptr->envelope.current_gain) >> 15;
					int32_t mono_sample = ((int32_t)raw_sample * sample_vol) >> 15;

					accumulator_l += (mono_sample * v_ptr->pan_l) >> 15;
					accumulator_r += (mono_sample * v_ptr->pan_r) >> 15;
				} else {
					v_ptr->phase_acc = 0;
				}
			}

			/* Clamp the stereo channels and write to interleaved buffer */
			buffer[buf_idx * 2] = (q15_t)CLAMP(accumulator_l >> MIXER_SHIFT, -32768, 32767);
			buffer[buf_idx * 2 + 1] = (q15_t)CLAMP(accumulator_r >> MIXER_SHIFT, -32768, 32767);
		}

		rendered += chunk;
	}
}
```

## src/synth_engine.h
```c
/*
 * Copyright 2026 Jan-Willem Smaal <usenet@gispen.org>
 * SPDX-License-Identifier: Apache-2.0
 */

/**
 * @file synth_engine.h
 * @brief Digital Signal Processing core for the synthesizer
 * @author Jan-Willem Smaal <usenet@gispen.org>
 */

#ifndef SYNTH_ENGINE_H
#define SYNTH_ENGINE_H

#include <stdint.h>
#include "adsr.h"

/** @brief Maximum waveform layers per patch */
#define PATCH_MAX_LAYERS 2

/** @brief Maximum unison voices per note per layer */
#define PATCH_MAX_UNISON 4

/**
 * @brief Event types for the synthesizer message queue
 */
enum synth_event_type {
	SYNTH_EVT_NOTE_ON,
	SYNTH_EVT_NOTE_OFF,
	SYNTH_EVT_SET_PATCH, /**< Change the globally active patch */
};

/**
 * @brief Waveform identifiers.
 *
 * The order must match the wave_table[] pointer array in synth_engine.c.
 * New waveforms must be inserted before SYNTH_WAVE_COUNT.
 */
enum synth_wave {
	SYNTH_WAVE_SINE,
	SYNTH_WAVE_SAW,
	SYNTH_WAVE_SQUARE,
	SYNTH_WAVE_TRI,
	SYNTH_WAVE_COUNT, /**< Sentinel — number of waveforms; do not use as a waveform */
};

/**
 * @brief Synthesizer patch (preset) descriptor.
 *
 * Each patch fully specifies the timbre: waveform layers, octave offsets,
 * unison voice count, detune spread, and ADSR envelope timing.  The
 * effective polyphony is MAX_VOICES / (layer_count * unison_count).
 */
struct patch {
	const char       *name;                          /**< Human-readable preset name */
	uint8_t           layer_count;                   /**< Number of waveform layers (1..PATCH_MAX_LAYERS) */
	enum synth_wave   wave[PATCH_MAX_LAYERS];         /**< Waveform per layer */
	int8_t            octave_shift[PATCH_MAX_LAYERS]; /**< Semitone octave offset per layer */
	uint8_t           unison_count;                  /**< Detuned voices per note per layer (1..PATCH_MAX_UNISON) */
	int16_t           detune_cents;                  /**< Total detune spread in cents; 0 = no detune */
	struct adsr_param env;                           /**< Envelope parameters for this patch */
};

/**
 * @brief Synthesizer event structure passed through the message queue
 */
struct synth_event {
	enum synth_event_type type;
	uint8_t patch_idx; /**< Active patch index (NOTE_ON and SET_PATCH events) */
	uint8_t note;      /**< MIDI note number */
	uint8_t velocity;  /**< MIDI velocity */
};

/**
 * @brief Submit an event to the synthesizer core.
 *
 * Safe to call from any thread or ISR context.  Drops the event silently
 * if the internal queue is full, to avoid blocking the caller.
 *
 * @param evt Pointer to the event to submit
 */
void synth_submit_event(struct synth_event *evt);

/**
 * @brief Initialize the synthesizer DSP core
 */
void synth_engine_init(void);

/**
 * @brief Render a block of audio samples.
 *
 * Processes all pending events, advances ADSR envelopes, and fills the
 * output buffer with interleaved stereo Q1.15 samples.
 *
 * @param buffer  Output buffer (interleaved stereo, Q1.15)
 * @param samples Number of samples per channel to render
 */
void synth_engine_render_block(int16_t *buffer, uint32_t samples);

/**
 * @brief Return the index of the currently active patch.
 *
 * Safe to call from any thread context (uses atomic read).
 *
 * @return Patch index into the internal patch table
 */
int synth_get_active_patch_idx(void);

/**
 * @brief Return a pointer to a patch by index.
 *
 * @param idx Patch index
 * @return Pointer to the @ref patch, or NULL if out of range
 */
const struct patch *synth_get_patch(int idx);

/**
 * @brief Return the total number of available patches.
 *
 * @return Number of entries in the internal patch table
 */
int synth_get_patch_count(void);

#endif /* SYNTH_ENGINE_H */
```

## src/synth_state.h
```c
/*
 * Copyright 2026 Jan-Willem Smaal <usenet@gispen.org>
 * SPDX-License-Identifier: Apache-2.0
 */

/**
 * @file synth_state.h
 * @brief Thread-safe shared state for the MIDI synthesizer
 * @author Jan-Willem Smaal <usenet@gispen.org>
 */

#ifndef SYNTH_STATE_H
#define SYNTH_STATE_H

#include <zephyr/kernel.h>
#include <arm_math.h>
#include <stdint.h>
#include <stdbool.h>

/* These can be 2, 4, 8, 16 or 32 */
#define MAX_VOICES CONFIG_VOICECARD_VOICES

/**
 * @brief Calculate the fixed bit-shift required to prevent overflow 
 * based on the maximum possible voices. This ensures consistent note 
 * volume across different MCU configurations.
 */
#if MAX_VOICES <= 1
  #define MIXER_SHIFT 0
#elif MAX_VOICES <= 2
  #define MIXER_SHIFT 1
#elif MAX_VOICES <= 4
  #define MIXER_SHIFT 2
#elif MAX_VOICES <= 8
  #define MIXER_SHIFT 3
#elif MAX_VOICES <= 16
  #define MIXER_SHIFT 4
#else
  #define MIXER_SHIFT 5
#endif

/**
 * @brief Represents a single "Voice Card"
 */
struct voice_card {
	bool gate_open;             /**< Simple square envelope gate */
	uint8_t note;               /**< MIDI note number */
	q15_t velocity_scale;       /**< Amplitude scale factor (Q15) */
	uint32_t phase_inc;         /**< 32-bit phase increment */
	uint32_t phase_acc;         /**< 32-bit phase accumulator */
	uint32_t age;               /**< Incremented on every Note On to track oldest note */
};

/**
 * @brief Shared synthesizer state
 */
struct synth_state {
	struct k_mutex lock;        /**< Mutex for thread-safe access */
	struct voice_card voices[MAX_VOICES];
	uint32_t note_counter;      /**< Global counter to assign age to notes */
};

/**
 * @brief Global lookup table for MIDI Note to 32-bit Phase Increment.
 * Derivied from midi1 library frequencies during startup.
 */
extern uint32_t phase_inc_lut[128];

/**
 * @brief Global lookup table mapping MIDI Velocity (0-127) to Q15 amplitude scale.
 */
extern q15_t velocity_lut[128];

#endif /* SYNTH_STATE_H */
```

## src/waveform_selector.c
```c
/*
 * Copyright 2026 Jan-Willem Smaal <usenet@gispen.org>
 * SPDX-License-Identifier: Apache-2.0
 */

/**
 * @file waveform_selector.c
 * @brief SW2 push-button waveform selector
 *
 * Each press of SW2 posts a SYNTH_EVT_SET_WAVE event to the synthesiser
 * message queue, cycling through the synth_wave enum in order.  Adding a
 * new waveform only requires extending the enum; no change is needed here.
 *
 * The GPIO callback runs in ISR context and only posts to the message queue,
 * keeping the ISR path short and lock-free.
 *
 * @author Jan-Willem Smaal <usenet@gispen.org>
 * @date 2026-06-16
 */

#include <zephyr/kernel.h>
#include <zephyr/drivers/gpio.h>
#include <zephyr/logging/log.h>
#include "synth_engine.h"
#include "waveform_selector.h"

LOG_MODULE_DECLARE(midi_synth, CONFIG_LOG_DEFAULT_LEVEL);

/* SW2 is defined in the board DTSI; enabled via the overlay. */
#define SW2_NODE DT_ALIAS(sw2)

BUILD_ASSERT(DT_NODE_EXISTS(SW2_NODE),
	     "sw2 alias not found in devicetree — check the board overlay");

static const struct gpio_dt_spec sw2 = GPIO_DT_SPEC_GET(SW2_NODE, gpios);

static struct gpio_callback sw2_cb_data;

/**
 * @brief ISR callback for SW2 press.
 *
 * Reads the current active waveform, advances to the next value in
 * the @ref synth_wave enum (wrapping at SYNTH_WAVE_COUNT), then posts
 * a SYNTH_EVT_SET_WAVE event to the synthesiser queue.
 */
static void sw2_pressed(const struct device *dev,
			struct gpio_callback *cb,
			uint32_t pins)
{
	struct synth_event evt;
	int next;

	ARG_UNUSED(dev);
	ARG_UNUSED(cb);
	ARG_UNUSED(pins);

	next = (synth_get_active_patch_idx() + 1) % synth_get_patch_count();

	evt.type = SYNTH_EVT_SET_PATCH;
	evt.patch_idx = (uint8_t)next;
	evt.note = 0;
	evt.velocity = 0;

	synth_submit_event(&evt);
}

int waveform_selector_init(void)
{
	int ret;

	if (!gpio_is_ready_dt(&sw2)) {
		LOG_ERR("SW2 GPIO device not ready");
		return -ENODEV;
	}

	ret = gpio_pin_configure_dt(&sw2, GPIO_INPUT);
	if (ret < 0) {
		LOG_ERR("SW2 gpio_pin_configure_dt failed: %d", ret);
		return ret;
	}

	ret = gpio_pin_interrupt_configure_dt(&sw2, GPIO_INT_EDGE_TO_ACTIVE);
	if (ret < 0) {
		LOG_ERR("SW2 interrupt configure failed: %d", ret);
		return ret;
	}

	gpio_init_callback(&sw2_cb_data, sw2_pressed, BIT(sw2.pin));
	gpio_add_callback(sw2.port, &sw2_cb_data);

	LOG_INF("Waveform selector ready (SW2 = gpio%d pin %d)",
		sw2.port->name[strlen(sw2.port->name) - 1], sw2.pin);

	return 0;
}
```

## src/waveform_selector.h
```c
/*
 * Copyright 2026 Jan-Willem Smaal <usenet@gispen.org>
 * SPDX-License-Identifier: Apache-2.0
 */

/**
 * @file waveform_selector.h
 * @brief SW2 push-button waveform selector API
 * @author Jan-Willem Smaal <usenet@gispen.org>
 * @date 2026-06-16
 */

#ifndef WAVEFORM_SELECTOR_H
#define WAVEFORM_SELECTOR_H

/**
 * @brief Initialise the waveform selector.
 *
 * Configures SW2 as an interrupt-driven input.  Each press cycles the
 * global synthesiser waveform through the values defined in
 * @ref synth_wave, wrapping back to the first after the last.
 *
 * @return 0 on success, negative error code on failure.
 */
int waveform_selector_init(void);

#endif /* WAVEFORM_SELECTOR_H */
```
